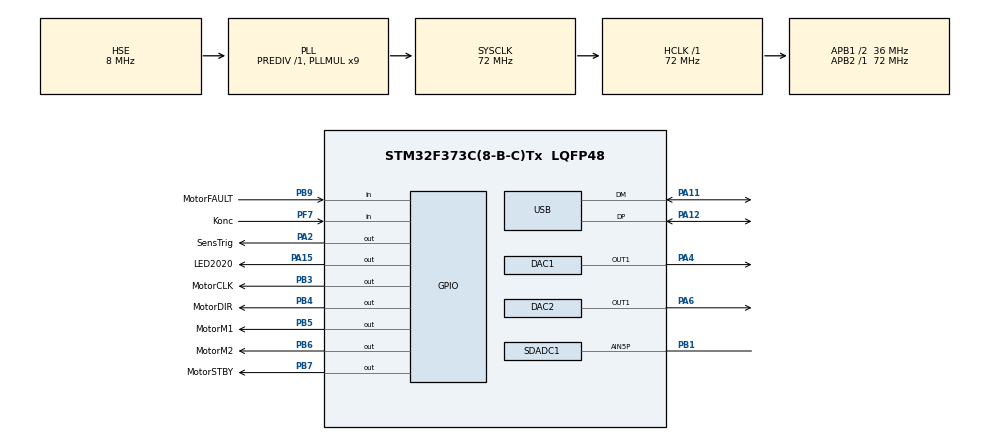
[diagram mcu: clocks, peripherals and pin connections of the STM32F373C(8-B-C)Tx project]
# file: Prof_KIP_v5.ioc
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Mcu.Family=STM32F3
Mcu.Name=STM32F373C(8-B-C)Tx
Mcu.Package=LQFP48
NVIC.PriorityGroup=NVIC_PRIORITYGROUP_4
NVIC.USB_LP_IRQn=true\:4\:0\:false\:false\:true\:false\:true\:true
PA11.Mode=Device
PA11.Signal=USB_DM
PA12.Mode=Device
PA12.Signal=USB_DP
PA13.Mode=Serial_Wire
PA13.Signal=SYS_JTMS-SWDIO
PA14.Mode=Serial_Wire
PA14.Signal=SYS_JTCK-SWCLK
PA15.GPIO_Label=LED2020
PA15.Signal=GPIO_Output
PA2.GPIO_Label=SensTrig
PA2.Signal=GPIO_Output
PA4.Signal=COMP_DAC11_group
PA6.Signal=COMP_DAC21_group
PB1.Mode=IN5-Single-Ended zero reference
PB1.Signal=SDADC1_AIN5P
PB3.GPIO_Label=MotorCLK
PB3.Signal=GPIO_Output
PB4.GPIO_Label=MotorDIR
PB4.Signal=GPIO_Output
PB5.GPIO_Label=MotorM1
PB5.Signal=GPIO_Output
PB6.GPIO_Label=MotorM2
PB6.Signal=GPIO_Output
PB7.GPIO_Label=MotorSTBY
PB7.Signal=GPIO_Output
PB9.GPIO_Label=MotorFAULT
PB9.Signal=GPIO_Input
PF0-OSC_IN.Mode=HSE-External-Oscillator
PF0-OSC_IN.Signal=RCC_OSC_IN
PF1-OSC_OUT.Mode=HSE-External-Oscillator
PF1-OSC_OUT.Signal=RCC_OSC_OUT
PF7.GPIO_Label=Konc
PF7.Signal=GPIO_Input
ProjectManager.HeapSize=0x200
ProjectManager.StackSize=0x400
ProjectManager.TargetToolchain=STM32CubeIDE
RCC.AHBFreq_Value=72000000
RCC.APB1CLKDivider=RCC_HCLK_DIV2
RCC.APB1Freq_Value=36000000
RCC.APB1TimFreq_Value=72000000
RCC.APB2Freq_Value=72000000
RCC.APB2TimFreq_Value=72000000
RCC.CortexFreq_Value=72000000
RCC.HCLKFreq_Value=72000000
RCC.HSE_VALUE=8000000
RCC.HSI_VALUE=8000000
RCC.LSE_VALUE=32768
RCC.PLLMUL=RCC_PLL_MUL9
RCC.PRESCALERUSB=RCC_USBCLKSOURCE_PLL_DIV1_5
RCC.SDADCPresc=RCC_SDADCSYSCLK_DIV12
RCC.SYSCLKFreq_VALUE=72000000
RCC.SYSCLKSource=RCC_SYSCLKSOURCE_PLLCLK
RCC.USBFreq_Value=48000000
SDADC1.FastConversionMode=SDADC_FAST_CONV_ENABLE
SDADC1.NbrOfConversionFlag=1
SH.COMP_DAC11_group.0=DAC1_OUT1,DAC_OUT1
SH.COMP_DAC21_group.0=DAC2_OUT1,DAC_OUT1
USB_DEVICE.CLASS_NAME_FS=CDC
USB_DEVICE.VirtualMode=Cdc
USB_DEVICE.VirtualModeFS=Cdc_FS
VP_USB_DEVICE_VS_USB_DEVICE_CDC_FS.Mode=CDC_FS
board=custom

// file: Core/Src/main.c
/* USER CODE BEGIN Header */
/**
  ******************************************************************************
  * @file           : main.c
  * @brief          : Main program body
  ******************************************************************************
  * @attention
  *
  * Copyright (c) 2026 STMicroelectronics.
  * All rights reserved.
  *
  * This software is licensed under terms that can be found in the LICENSE file
  * in the root directory of this software component.
  * If no LICENSE file comes with this software, it is provided AS-IS.
  *
  ******************************************************************************
  */
/* USER CODE END Header */
#include "main.h"
#include "usb_device.h"

/* USER CODE BEGIN Includes */
#include "dac_sine.h"
#include "instrument_app.h"
#include "firmware_update.h"
/* USER CODE END Includes */

DAC_HandleTypeDef hdac1;
DAC_HandleTypeDef hdac2;

SDADC_HandleTypeDef hsdadc1;

void SystemClock_Config(void);
static void MX_GPIO_Init(void);
static void MX_DAC1_Init(void);
static void MX_DAC2_Init(void);
static void MX_SDADC1_Init(void);

int main(void)
{

  /* USER CODE BEGIN 1 */
  /* Держим D+ в нуле, пока USB не будет готов: подтяжка на плате постоянная,
     и без этого хост может начать перечисление раньше, чем поднимется USB,
     а после обновления вообще не заметить смены устройства. Удержание снимает
     HAL_PCD_MspInit при инициализации USB (PA11/PA12 -> AF). */
  Firmware_UsbHold();
  /* Если предыдущая сессия загрузила новое ПО - сначала переносим его на место
     приложения (копировщик .copyer) и перезапускаемся. Делается до HAL_Init(),
     потому что копировщик работает только с регистрами флеша. */
  Firmware_BootCheck();
  /* USER CODE END 1 */

  /* MCU Configuration--------------------------------------------------------*/

  /* Reset of all peripherals, Initializes the Flash interface and the Systick. */
  HAL_Init();

  /* Configure the system clock */
  SystemClock_Config();

  /* Initialize all configured peripherals */
  MX_GPIO_Init();
  MX_DAC1_Init();
  MX_DAC2_Init();
  MX_SDADC1_Init();
  MX_USB_DEVICE_Init();
  /* USER CODE BEGIN 2 */
  /* TIM3 + DMA: 32 points, 8 kHz, both DACs and SensTrig. */
  DAC_Sine_Init();
  DAC_Sine_Start();
  Instrument_Init();
  /* USER CODE END 2 */

  /* Infinite loop */
  while (1)
  {

    /* USER CODE BEGIN 3 */
    Instrument_Poll();
  }
  /* USER CODE END 3 */
}

void SystemClock_Config(void)
{
  RCC_OscInitTypeDef RCC_OscInitStruct = {0};
  RCC_ClkInitTypeDef RCC_ClkInitStruct = {0};
  RCC_PeriphCLKInitTypeDef PeriphClkInit = {0};

  /** Initializes the RCC Oscillators according to the specified parameters
  * in the RCC_OscInitTypeDef structure.
  */
  RCC_OscInitStruct.OscillatorType = RCC_OSCILLATORTYPE_HSE;
  RCC_OscInitStruct.HSEState = RCC_HSE_ON;
  RCC_OscInitStruct.HSEPredivValue = RCC_HSE_PREDIV_DIV1;
  RCC_OscInitStruct.HSIState = RCC_HSI_ON;
  RCC_OscInitStruct.PLL.PLLState = RCC_PLL_ON;
  RCC_OscInitStruct.PLL.PLLSource = RCC_PLLSOURCE_HSE;
  RCC_OscInitStruct.PLL.PLLMUL = RCC_PLL_MUL9;
  if (HAL_RCC_OscConfig(&RCC_OscInitStruct) != HAL_OK)
  {
    Error_Handler();
  }

  /** Initializes the CPU, AHB and APB buses clocks
  */
  RCC_ClkInitStruct.ClockType = RCC_CLOCKTYPE_HCLK|RCC_CLOCKTYPE_SYSCLK
                              |RCC_CLOCKTYPE_PCLK1|RCC_CLOCKTYPE_PCLK2;
  RCC_ClkInitStruct.SYSCLKSource = RCC_SYSCLKSOURCE_PLLCLK;
  RCC_ClkInitStruct.AHBCLKDivider = RCC_SYSCLK_DIV1;
  RCC_ClkInitStruct.APB1CLKDivider = RCC_HCLK_DIV2;
  RCC_ClkInitStruct.APB2CLKDivider = RCC_HCLK_DIV1;

  if (HAL_RCC_ClockConfig(&RCC_ClkInitStruct, FLASH_LATENCY_2) != HAL_OK)
  {
    Error_Handler();
  }
  PeriphClkInit.PeriphClockSelection = RCC_PERIPHCLK_USB|RCC_PERIPHCLK_SDADC;
  PeriphClkInit.USBClockSelection = RCC_USBCLKSOURCE_PLL_DIV1_5;
  PeriphClkInit.SdadcClockSelection = RCC_SDADCSYSCLK_DIV12;
  if (HAL_RCCEx_PeriphCLKConfig(&PeriphClkInit) != HAL_OK)
  {
    Error_Handler();
  }
  HAL_PWREx_EnableSDADC(PWR_SDADC_ANALOG1);
}

static void MX_DAC1_Init(void)
{

  DAC_ChannelConfTypeDef sConfig = {0};

  /** DAC Initialization
  */
  hdac1.Instance = DAC1;
  if (HAL_DAC_Init(&hdac1) != HAL_OK)
  {
    Error_Handler();
  }

  /** DAC channel OUT1 config
  */
  sConfig.DAC_Trigger = DAC_TRIGGER_NONE;
  sConfig.DAC_OutputBuffer = DAC_OUTPUTBUFFER_ENABLE;
  if (HAL_DAC_ConfigChannel(&hdac1, &sConfig, DAC_CHANNEL_1) != HAL_OK)
  {
    Error_Handler();
  }

}

static void MX_DAC2_Init(void)
{

  DAC_ChannelConfTypeDef sConfig = {0};

  /** DAC Initialization
  */
  hdac2.Instance = DAC2;
  if (HAL_DAC_Init(&hdac2) != HAL_OK)
  {
    Error_Handler();
  }

  /** DAC channel OUT1 config
  */
  sConfig.DAC_Trigger = DAC_TRIGGER_NONE;
  sConfig.DAC_OutputBuffer = DAC_OUTPUTBUFFER_ENABLE;
  if (HAL_DAC_ConfigChannel(&hdac2, &sConfig, DAC_CHANNEL_1) != HAL_OK)
  {
    Error_Handler();
  }

}

static void MX_SDADC1_Init(void)
{

  /** Configure the SDADC low power mode, fast conversion mode,
  slow clock mode and SDADC1 reference voltage
  */
  hsdadc1.Instance = SDADC1;
  hsdadc1.Init.IdleLowPowerMode = SDADC_LOWPOWER_NONE;
  hsdadc1.Init.FastConversionMode = SDADC_FAST_CONV_ENABLE;
  hsdadc1.Init.SlowClockMode = SDADC_SLOW_CLOCK_DISABLE;
  hsdadc1.Init.ReferenceVoltage = SDADC_VREF_EXT;
  if (HAL_SDADC_Init(&hsdadc1) != HAL_OK)
  {
    Error_Handler();
  }

}

static void MX_GPIO_Init(void)
{
  GPIO_InitTypeDef GPIO_InitStruct = {0};

  /* GPIO Ports Clock Enable */
  __HAL_RCC_GPIOF_CLK_ENABLE();
  __HAL_RCC_GPIOA_CLK_ENABLE();
  __HAL_RCC_GPIOB_CLK_ENABLE();

  /*Configure GPIO pin Output Level */
  HAL_GPIO_WritePin(GPIOA, SensTrig_Pin|LED2020_Pin, GPIO_PIN_RESET);

  /*Configure GPIO pin Output Level */
  HAL_GPIO_WritePin(GPIOB, MotorCLK_Pin|MotorDIR_Pin|MotorM1_Pin|MotorM2_Pin
                          |MotorSTBY_Pin, GPIO_PIN_RESET);

  /*Configure GPIO pins : SensTrig_Pin LED2020_Pin */
  GPIO_InitStruct.Pin = SensTrig_Pin|LED2020_Pin;
  GPIO_InitStruct.Mode = GPIO_MODE_OUTPUT_PP;
  GPIO_InitStruct.Pull = GPIO_NOPULL;
  GPIO_InitStruct.Speed = GPIO_SPEED_FREQ_LOW;
  HAL_GPIO_Init(GPIOA, &GPIO_InitStruct);

  /*Configure GPIO pin : Konc_Pin */
  GPIO_InitStruct.Pin = Konc_Pin;
  GPIO_InitStruct.Mode = GPIO_MODE_INPUT;
  GPIO_InitStruct.Pull = GPIO_NOPULL;
  HAL_GPIO_Init(Konc_GPIO_Port, &GPIO_InitStruct);

  /*Configure GPIO pins : MotorCLK_Pin MotorDIR_Pin MotorM1_Pin MotorM2_Pin
                           MotorSTBY_Pin */
  GPIO_InitStruct.Pin = MotorCLK_Pin|MotorDIR_Pin|MotorM1_Pin|MotorM2_Pin
                          |MotorSTBY_Pin;
  GPIO_InitStruct.Mode = GPIO_MODE_OUTPUT_PP;
  GPIO_InitStruct.Pull = GPIO_NOPULL;
  GPIO_InitStruct.Speed = GPIO_SPEED_FREQ_LOW;
  HAL_GPIO_Init(GPIOB, &GPIO_InitStruct);

}

void Error_Handler(void)
{
  /* USER CODE BEGIN Error_Handler_Debug */
  /* Fail closed: stop pulse timer and put the driver into standby. */
  __HAL_RCC_TIM2_CLK_ENABLE();
  TIM2->CR1 = 0;
  MotorSTBY_GPIO_Port->BSRR = (uint32_t)MotorSTBY_Pin << 16;
  /* User can add his own implementation to report the HAL error return state */
  __disable_irq();
  while (1)
  {
  }
  /* USER CODE END Error_Handler_Debug */
}
